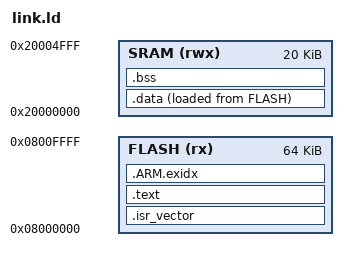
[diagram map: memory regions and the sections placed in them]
ENTRY(Reset_Handler)

MEMORY
{
    FLASH (rx)  : ORIGIN = 0x08000000, LENGTH = 64K
    SRAM  (rwx) : ORIGIN = 0x20000000, LENGTH = 20K
}

_estack = ORIGIN(SRAM) + LENGTH(SRAM);

SECTIONS
{
    .isr_vector ORIGIN(FLASH) : ALIGN(256)
    {
        KEEP(*(.isr_vector))
    } > FLASH

    .text :
    {
        . = ALIGN(4);
        *(.text*)
        *(.rodata*)
        . = ALIGN(4);
    } > FLASH

    /* ARM exception index, if emitted */
    .ARM.exidx :
    {
        *(.ARM.exidx*)
    } > FLASH

    .data :
    {
        . = ALIGN(4);
        _sdata = .;
        *(.data*)
        . = ALIGN(4);
        _edata = .;
    } > SRAM AT > FLASH

    _sidata = LOADADDR(.data);

    .bss (NOLOAD) :
    {
        . = ALIGN(4);
        _sbss = .;
        *(.bss*)
        *(COMMON)
        . = ALIGN(4);
        _ebss = .;
    } > SRAM

    . = ALIGN(8);
    _end = .;

    /DISCARD/ :
    {
        *(.comment*)
        *(.note*)
        *(.eh_frame*)
    }
}
